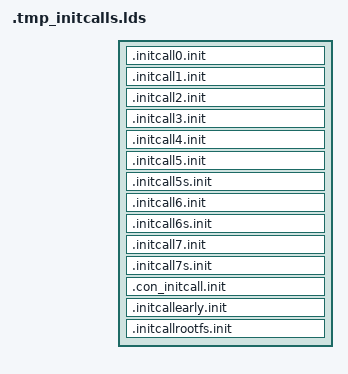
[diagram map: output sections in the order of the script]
SECTIONS {
	.initcall0.init : {
		*(.initcall0.init..kmod_shm__382_143_ipc_ns_init) ;
		*(.initcall0.init..kmod_min_addr__227_53_init_mmap_min_addr) ;
		*(.initcall0.init..kmod_pci__425_6677_pci_realloc_setup_params) ;
		*(.initcall0.init..kmod_net_namespace__599_1121_net_ns_init) ;
		*(.initcall0.init..kmod_inet_fragment__625_216_inet_frag_wq_init) ;
	}
	.initcall1.init : {
		*(.initcall1.init..kmod_e820__336_792_e820__register_nvs_regions) ;
		*(.initcall1.init..kmod_tsc__194_1029_cpufreq_register_tsc_scaling) ;
		*(.initcall1.init..kmod_reboot__371_525_reboot_init) ;
		*(.initcall1.init..kmod_apic__636_2793_init_lapic_sysfs) ;
		*(.initcall1.init..kmod_cpu__564_1558_alloc_frozen_cpus) ;
		*(.initcall1.init..kmod_cpu__566_1605_cpu_hotplug_pm_sync_init) ;
		*(.initcall1.init..kmod_workqueue__552_5647_wq_sysfs_init) ;
		*(.initcall1.init..kmod_ksysfs__245_269_ksysfs_init) ;
		*(.initcall1.init..kmod_cpufreq_schedutil__872_831_schedutil_gov_init) ;
		*(.initcall1.init..kmod_main__333_959_pm_init) ;
		*(.initcall1.init..kmod_hibernate__497_1271_pm_disk_init) ;
		*(.initcall1.init..kmod_swap__328_1613_swsusp_header_init) ;
		*(.initcall1.init..kmod_update__495_240_rcu_set_runtime_mode) ;
		*(.initcall1.init..kmod_jiffies__103_88_init_jiffies_clocksource) ;
		*(.initcall1.init..kmod_futex__347_4038_futex_init) ;
		*(.initcall1.init..kmod_cgroup__846_5876_cgroup_wq_init) ;
		*(.initcall1.init..kmod_cgroup_v1__363_1246_cgroup1_wq_init) ;
		*(.initcall1.init..kmod_trace_kprobe__325_1921_init_kprobe_trace_early) ;
		*(.initcall1.init..kmod_fsnotify__273_572_fsnotify_init) ;
		*(.initcall1.init..kmod_locks__492_3074_filelock_init) ;
		*(.initcall1.init..kmod_binfmt_misc__289_834_init_misc_binfmt) ;
		*(.initcall1.init..kmod_binfmt_script__201_156_init_script_binfmt) ;
		*(.initcall1.init..kmod_binfmt_elf__296_2311_init_elf_binfmt) ;
		*(.initcall1.init..kmod_compat_binfmt_elf__298_2311_init_compat_elf_binfmt) ;
		*(.initcall1.init..kmod_debugfs__283_851_debugfs_init) ;
		*(.initcall1.init..kmod_tracefs__253_552_tracefs_init) ;
		*(.initcall1.init..kmod_random32__401_489_prandom_init_early) ;
		*(.initcall1.init..kmod_iommu__402_2686_iommu_init) ;
		*(.initcall1.init..kmod_component__213_123_component_debug_init) ;
		*(.initcall1.init..kmod_trace__348_292_early_resume_init) ;
		*(.initcall1.init..kmod_cpufreq__572_2899_cpufreq_core_init) ;
		*(.initcall1.init..kmod_cpufreq_performance__180_44_cpufreq_gov_performance_init) ;
		*(.initcall1.init..kmod_cpufreq_userspace__186_141_cpufreq_gov_userspace_init) ;
		*(.initcall1.init..kmod_cpufreq_ondemand__198_477_CPU_FREQ_GOV_ONDEMAND_init) ;
		*(.initcall1.init..kmod_cpuidle__521_779_cpuidle_init) ;
		*(.initcall1.init..kmod_socket__658_3119_sock_init) ;
		*(.initcall1.init..kmod_sock__820_3497_net_inuse_init) ;
		*(.initcall1.init..kmod_net_namespace__566_384_net_defaults_init) ;
		*(.initcall1.init..kmod_flow_dissector__679_1832_init_default_flow_dissectors) ;
		*(.initcall1.init..kmod_netpoll__671_796_netpoll_init) ;
		*(.initcall1.init..kmod_af_netlink__689_2911_netlink_proto_init) ;
		*(.initcall1.init..kmod_genetlink__571_1443_genl_init) ;
		*(.initcall1.init..kmod_cpu__410_397_bsp_pm_check_init) ;
	}
	.initcall2.init : {
		*(.initcall2.init..kmod_irqdesc__175_331_irq_sysfs_init) ;
		*(.initcall2.init..kmod_audit__575_1677_audit_init) ;
		*(.initcall2.init..kmod_tracepoint__189_140_release_early_probes) ;
		*(.initcall2.init..kmod_backing_dev__527_230_bdi_class_init) ;
		*(.initcall2.init..kmod_mm_init__269_204_mm_sysfs_init) ;
		*(.initcall2.init..kmod_page_alloc__657_8484_init_per_zone_wmark_min) ;
		*(.initcall2.init..kmod_mpi__239_64_mpi_init) ;
		*(.initcall2.init..kmod_kobject_uevent__547_814_kobject_uevent_init) ;
		*(.initcall2.init..kmod_probe__261_108_pcibus_class_init) ;
		*(.initcall2.init..kmod_pci_driver__389_1661_pci_driver_init) ;
		*(.initcall2.init..kmod_backlight__360_770_backlight_class_init) ;
		*(.initcall2.init..kmod_tty_io__299_3559_tty_class_init) ;
		*(.initcall2.init..kmod_vt__303_4286_vtconsole_class_init) ;
		*(.initcall2.init..kmod_iommu_sysfs__236_47_iommu_dev_init) ;
		*(.initcall2.init..kmod_drm_mipi_dsi__378_1209_mipi_dsi_bus_init) ;
		*(.initcall2.init..kmod_core__394_606_devlink_class_init) ;
		*(.initcall2.init..kmod_swnode__215_1167_software_node_init) ;
		*(.initcall2.init..kmod_wakeup__542_1188_wakeup_sources_debugfs_init) ;
		*(.initcall2.init..kmod_wakeup_stats__165_217_wakeup_sources_sysfs_init) ;
		*(.initcall2.init..kmod_node__327_1073_register_node_type) ;
		*(.initcall2.init..kmod_regmap__457_3316_regmap_initcall) ;
		*(.initcall2.init..kmod_i2c_core__475_2090_i2c_init) ;
		*(.initcall2.init..kmod_thermal_sys__413_1489_thermal_init) ;
		*(.initcall2.init..kmod_menu__155_579_init_menu) ;
		*(.initcall2.init..kmod_pcc__178_615_pcc_init) ;
		*(.initcall2.init..kmod_amd_bus__253_404_amd_postcore_init) ;
	}
	.initcall3.init : {
		*(.initcall3.init..kmod_bts__264_619_bts_init) ;
		*(.initcall3.init..kmod_pt__306_1761_pt_init) ;
		*(.initcall3.init..kmod_ksysfs__234_356_boot_params_ksysfs_init) ;
		*(.initcall3.init..kmod_bootflag__259_102_sbf_init) ;
		*(.initcall3.init..kmod_kdebugfs__230_176_arch_kdebugfs_init) ;
		*(.initcall3.init..kmod_intel_pconfig__10_82_intel_pconfig_init) ;
		*(.initcall3.init..kmod_if__201_424_mtrr_if_init) ;
		*(.initcall3.init..kmod_cstate__192_214_ffh_cstate_init) ;
		*(.initcall3.init..kmod_kcmp__270_239_kcmp_cookies_init) ;
		*(.initcall3.init..kmod_cryptomgr__359_269_cryptomgr_init) ;
		*(.initcall3.init..kmod_pci_acpi__275_1389_acpi_pci_init) ;
		*(.initcall3.init..kmod_dmaengine__263_293_dma_channel_table_init) ;
		*(.initcall3.init..kmod_dmaengine__339_1659_dma_bus_init) ;
		*(.initcall3.init..kmod_dma_iommu__297_1428_iommu_dma_init) ;
		*(.initcall3.init..kmod_dmi_id__169_255_dmi_id_init) ;
		*(.initcall3.init..kmod_init__245_51_pci_arch_init) ;
	}
	.initcall4.init : {
		*(.initcall4.init..kmod_vma__339_457_init_vdso) ;
		*(.initcall4.init..kmod_vdso32_setup__67_63_sysenter_setup) ;
		*(.initcall4.init..kmod_core__304_6346_fixup_ht_bug) ;
		*(.initcall4.init..kmod_topology__168_167_topology_init) ;
		*(.initcall4.init..kmod_intel_epb__159_216_intel_epb_init) ;
		*(.initcall4.init..kmod_mtrr__251_887_mtrr_init_finialize) ;
		*(.initcall4.init..kmod_user__147_226_uid_cache_init) ;
		*(.initcall4.init..kmod_params__303_956_param_sysfs_init) ;
		*(.initcall4.init..kmod_ucount__155_319_user_namespace_sysctl_init) ;
		*(.initcall4.init..kmod_stats__708_128_proc_schedstat_init) ;
		*(.initcall4.init..kmod_poweroff__69_45_pm_sysrq_init) ;
		*(.initcall4.init..kmod_profile__261_565_create_proc_profile) ;
		*(.initcall4.init..kmod_crash_core__235_482_crash_save_vmcoreinfo_init) ;
		*(.initcall4.init..kmod_kexec_core__347_1119_crash_notes_memory_init) ;
		*(.initcall4.init..kmod_cgroup__861_6744_cgroup_sysfs_init) ;
		*(.initcall4.init..kmod_namespace__253_157_cgroup_namespaces_init) ;
		*(.initcall4.init..kmod_kprobes__374_2530_init_optprobes) ;
		*(.initcall4.init..kmod_oom_kill__423_682_oom_init) ;
		*(.initcall4.init..kmod_backing_dev__529_247_default_bdi_init) ;
		*(.initcall4.init..kmod_percpu__452_3381_percpu_enable_async) ;
		*(.initcall4.init..kmod_compaction__514_3012_kcompactd_init) ;
		*(.initcall4.init..kmod_mmap__429_3741_init_user_reserve) ;
		*(.initcall4.init..kmod_mmap__433_3762_init_admin_reserve) ;
		*(.initcall4.init..kmod_mmap__435_3832_init_reserve_notifier) ;
		*(.initcall4.init..kmod_swap_state__336_911_swap_init_sysfs) ;
		*(.initcall4.init..kmod_swapfile__436_3822_swapfile_init) ;
		*(.initcall4.init..kmod_hugetlb__381_3607_hugetlb_init) ;
		*(.initcall4.init..kmod_io_wq__357_1157_io_wq_init) ;
		*(.initcall4.init..kmod_seqiv__270_183_seqiv_module_init) ;
		*(.initcall4.init..kmod_echainiv__270_160_echainiv_module_init) ;
		*(.initcall4.init..kmod_rsa_generic__246_281_rsa_init) ;
		*(.initcall4.init..kmod_cmac__114_311_crypto_cmac_module_init) ;
		*(.initcall4.init..kmod_hmac__266_254_hmac_module_init) ;
		*(.initcall4.init..kmod_crypto_null__262_221_crypto_null_mod_init) ;
		*(.initcall4.init..kmod_md5__115_245_md5_mod_init) ;
		*(.initcall4.init..kmod_sha256_generic__252_113_sha256_generic_mod_init) ;
		*(.initcall4.init..kmod_sha512_generic__252_221_sha512_generic_mod_init) ;
		*(.initcall4.init..kmod_cbc__112_218_crypto_cbc_module_init) ;
		*(.initcall4.init..kmod_ctr__115_355_crypto_ctr_module_init) ;
		*(.initcall4.init..kmod_gcm__282_1159_crypto_gcm_module_init) ;
		*(.initcall4.init..kmod_ccm__284_949_crypto_ccm_module_init) ;
		*(.initcall4.init..kmod_aes_generic__107_1314_aes_init) ;
		*(.initcall4.init..kmod_crc32c_generic__114_161_crc32c_mod_init) ;
		*(.initcall4.init..kmod_authenc__393_464_crypto_authenc_module_init) ;
		*(.initcall4.init..kmod_authencesn__391_479_crypto_authenc_esn_module_init) ;
		*(.initcall4.init..kmod_drbg__280_2146_drbg_init) ;
		*(.initcall4.init..kmod_ghash_generic__117_178_ghash_mod_init) ;
		*(.initcall4.init..kmod_bio__525_1620_init_bio) ;
		*(.initcall4.init..kmod_blk_ioc__314_422_blk_ioc_init) ;
		*(.initcall4.init..kmod_blk_mq__582_4018_blk_mq_init) ;
		*(.initcall4.init..kmod_genhd__333_836_genhd_device_init) ;
		*(.initcall4.init..kmod_slot__271_380_pci_slot_init) ;
		*(.initcall4.init..kmod_acpi__360_1344_acpi_init) ;
		*(.initcall4.init..kmod_pnp__250_234_pnp_init) ;
		*(.initcall4.init..kmod_misc__223_291_misc_init) ;
		*(.initcall4.init..kmod_iommu__299_143_iommu_subsys_init) ;
		*(.initcall4.init..kmod_vgaarb__279_1588_vga_arb_device_init) ;
		*(.initcall4.init..kmod_cn__555_283_cn_init) ;
		*(.initcall4.init..kmod_dma_buf__305_1481_dma_buf_init) ;
		*(.initcall4.init..kmod_scsi_mod__405_812_init_scsi) ;
		*(.initcall4.init..kmod_libata__519_6313_ata_init) ;
		*(.initcall4.init..kmod_libphy__463_3242_phy_init) ;
		*(.initcall4.init..kmod_pcmcia_core__283_918_init_pcmcia_cs) ;
		*(.initcall4.init..kmod_usb_common__327_412_usb_common_init) ;
		*(.initcall4.init..kmod_usbcore__365_1119_usb_init) ;
		*(.initcall4.init..kmod_serio__226_1052_serio_init) ;
		*(.initcall4.init..kmod_input_core__367_2634_input_init) ;
		*(.initcall4.init..kmod_rtc_core__255_469_rtc_init) ;
		*(.initcall4.init..kmod_pps_core__218_484_pps_init) ;
		*(.initcall4.init..kmod_ptp__329_453_ptp_init) ;
		*(.initcall4.init..kmod_power_supply__201_1380_power_supply_class_init) ;
		*(.initcall4.init..kmod_hwmon__316_1071_hwmon_init) ;
		*(.initcall4.init..kmod_md_mod__720_9898_md_init) ;
		*(.initcall4.init..kmod_led_class__179_539_leds_init) ;
		*(.initcall4.init..kmod_dmi_scan__277_804_dmi_init) ;
		*(.initcall4.init..kmod_efi__295_436_efisubsys_init) ;
		*(.initcall4.init..kmod_nvmem_core__305_1913_nvmem_init) ;
		*(.initcall4.init..kmod_soundcore__170_65_init_soundcore) ;
		*(.initcall4.init..kmod_snd__239_426_alsa_sound_init) ;
		*(.initcall4.init..kmod_snd_seq_device__235_311_alsa_seq_device_init) ;
		*(.initcall4.init..kmod_snd_hda_core__248_96_hda_bus_init) ;
		*(.initcall4.init..kmod_sock__827_3809_proto_init) ;
		*(.initcall4.init..kmod_dev__1551_11719_net_dev_init) ;
		*(.initcall4.init..kmod_neighbour__730_3740_neigh_init) ;
		*(.initcall4.init..kmod_fib_notifier__367_199_fib_notifier_init) ;
		*(.initcall4.init..kmod_fib_rules__678_1298_fib_rules_init) ;
		*(.initcall4.init..kmod_sch_api__638_2305_pktsched_init) ;
		*(.initcall4.init..kmod_cls_api__743_3919_tc_filter_init) ;
		*(.initcall4.init..kmod_act_api__585_1711_tc_action_init) ;
		*(.initcall4.init..kmod_ethtool_nl__557_1004_ethnl_init) ;
		*(.initcall4.init..kmod_nexthop__739_3747_nexthop_init) ;
		*(.initcall4.init..kmod_cipso_ipv4__641_2293_cipso_v4_init) ;
		*(.initcall4.init..kmod_mac80211__1817_1489_ieee80211_init) ;
		*(.initcall4.init..kmod_netlabel_kapi__596_1523_netlbl_init) ;
		*(.initcall4.init..kmod_rfkill__294_1398_rfkill_init) ;
		*(.initcall4.init..kmod_legacy__246_77_pci_subsys_init) ;
	}
	.initcall5.init : {
		*(.initcall5.init..kmod_nmi__344_102_nmi_warning_debugfs) ;
		*(.initcall5.init..kmod_microcode__237_908_save_microcode_in_initrd) ;
		*(.initcall5.init..kmod_hpet__177_1084_hpet_late_init) ;
		*(.initcall5.init..kmod_amd_nb__254_544_init_amd_nbs) ;
		*(.initcall5.init..kmod_resource__276_1915_iomem_init_inode) ;
		*(.initcall5.init..kmod_clocksource__194_1000_clocksource_done_booting) ;
		*(.initcall5.init..kmod_trace__418_9700_tracer_init_tracefs) ;
		*(.initcall5.init..kmod_trace_printk__278_393_init_trace_printk_function_export) ;
		*(.initcall5.init..kmod_trace_kprobe__327_1951_init_kprobe_trace) ;
		*(.initcall5.init..kmod_trace_dynevent__278_236_init_dynamic_event) ;
		*(.initcall5.init..kmod_trace_uprobe__334_1664_init_uprobe_trace) ;
		*(.initcall5.init..kmod_secretmem__327_255_secretmem_init) ;
		*(.initcall5.init..kmod_pipe__342_1449_init_pipe_fs) ;
		*(.initcall5.init..kmod_inotify_user__360_855_inotify_user_setup) ;
		*(.initcall5.init..kmod_eventpoll__651_2386_eventpoll_init) ;
		*(.initcall5.init..kmod_anon_inodes__241_241_anon_inode_init) ;
		*(.initcall5.init..kmod_locks__490_3051_proc_locks_init) ;
		*(.initcall5.init..kmod_iomap__443_1537_iomap_init) ;
		*(.initcall5.init..kmod_dquot__368_2988_dquot_init) ;
		*(.initcall5.init..kmod_netlink__305_103_quota_init) ;
		*(.initcall5.init..kmod_proc__192_19_proc_cmdline_init) ;
		*(.initcall5.init..kmod_proc__208_98_proc_consoles_init) ;
		*(.initcall5.init..kmod_proc__221_32_proc_cpuinfo_init) ;
		*(.initcall5.init..kmod_proc__290_60_proc_devices_init) ;
		*(.initcall5.init..kmod_proc__192_42_proc_interrupts_init) ;
		*(.initcall5.init..kmod_proc__229_33_proc_loadavg_init) ;
		*(.initcall5.init..kmod_proc__313_161_proc_meminfo_init) ;
		*(.initcall5.init..kmod_proc__210_242_proc_stat_init) ;
		*(.initcall5.init..kmod_proc__192_41_proc_uptime_init) ;
		*(.initcall5.init..kmod_proc__192_23_proc_version_init) ;
		*(.initcall5.init..kmod_proc__192_33_proc_softirqs_init) ;
		*(.initcall5.init..kmod_proc__279_697_proc_kcore_init) ;
		*(.initcall5.init..kmod_proc__287_1560_vmcore_init) ;
		*(.initcall5.init..kmod_proc__190_66_proc_kmsg_init) ;
		*(.initcall5.init..kmod_proc__319_338_proc_page_init) ;
		*(.initcall5.init..kmod_ramfs__307_295_init_ramfs_fs) ;
		*(.initcall5.init..kmod_hugetlbfs__314_1584_init_hugetlbfs_fs) ;
		*(.initcall5.init..kmod_scsi_ioctl__322_890_blk_scsi_ioctl_init) ;
		*(.initcall5.init..kmod_acpi__316_183_acpi_event_init) ;
		*(.initcall5.init..kmod_pnp__164_113_pnp_system_init) ;
		*(.initcall5.init..kmod_pnp__187_314_pnpacpi_init) ;
		*(.initcall5.init..kmod_mem__324_777_chr_dev_init) ;
		*(.initcall5.init..kmod_firmware_class__336_1576_firmware_class_init) ;
		*(.initcall5.init..kmod_pcmcia__299_1441_init_pcmcia_bus) ;
		*(.initcall5.init..kmod_acpi_pm__254_220_init_acpi_pm_clocksource) ;
		*(.initcall5.init..kmod_sysctl_net_core__599_663_sysctl_core_init) ;
		*(.initcall5.init..kmod_eth__617_505_eth_offload_init) ;
		*(.initcall5.init..kmod_af_inet__751_1929_ipv4_offload_init) ;
		*(.initcall5.init..kmod_af_inet__754_2062_inet_init) ;
		*(.initcall5.init..kmod_unix__588_2990_af_unix_init) ;
		*(.initcall5.init..kmod_ip6_offload__626_446_ipv6_offload_init) ;
		*(.initcall5.init..kmod_sunrpc__569_152_init_sunrpc) ;
		*(.initcall5.init..kmod_cfg80211__1734_1570_cfg80211_init) ;
		*(.initcall5.init..kmod_i386__259_373_pcibios_assign_resources) ;
	}
	.initcall5s.init : {
		*(.initcall5s.init..kmod_quirks__326_194_pci_apply_final_quirks) ;
		*(.initcall5s.init..kmod_acpi__305_142_acpi_reserve_resources) ;
	}
	.initcall6.init : {
		*(.initcall6.init..kmod_vdso32_setup__69_96_ia32_binfmt_init) ;
		*(.initcall6.init..kmod_rapl__267_859_rapl_pmu_init) ;
		*(.initcall6.init..kmod_uncore__268_670_amd_uncore_init) ;
		*(.initcall6.init..kmod_ibs__287_1069_amd_ibs_init) ;
		*(.initcall6.init..kmod_iommu__270_489_amd_iommu_pc_init) ;
		*(.initcall6.init..kmod_msr__258_308_msr_init) ;
		*(.initcall6.init..kmod_intel_uncore__306_1876_intel_uncore_init) ;
		*(.initcall6.init..kmod_intel_cstate__264_777_cstate_pmu_init) ;
		*(.initcall6.init..kmod_setup__393_1259_register_kernel_offset_dumper) ;
		*(.initcall6.init..kmod_i8259__204_434_i8259A_init_ops) ;
		*(.initcall6.init..kmod_tsc__199_1416_init_tsc_clocksource) ;
		*(.initcall6.init..kmod_rtc__298_207_add_rtc_cmos) ;
		*(.initcall6.init..kmod_i8237__95_76_i8237A_init_ops) ;
		*(.initcall6.init..kmod_umwait__316_238_umwait_init) ;
		*(.initcall6.init..kmod_msr__239_286_msr_init) ;
		*(.initcall6.init..kmod_cpuid__210_178_cpuid_init) ;
		*(.initcall6.init..kmod_io_apic__325_2462_ioapic_init_ops) ;
		*(.initcall6.init..kmod_pcspeaker__159_14_add_pcspkr) ;
		*(.initcall6.init..kmod_check__234_186_start_periodic_check_for_corruption) ;
		*(.initcall6.init..kmod_sysfb__332_70_sysfb_init) ;
		*(.initcall6.init..kmod_audit_64__231_83_audit_classes_init) ;
		*(.initcall6.init..kmod_iosf_mbi__269_566_iosf_mbi_init) ;
		*(.initcall6.init..kmod_exec_domain__264_35_proc_execdomains_init) ;
		*(.initcall6.init..kmod_panic__269_676_register_warn_debugfs) ;
		*(.initcall6.init..kmod_cpu__579_2525_cpuhp_sysfs_init) ;
		*(.initcall6.init..kmod_resource__241_145_ioresources_init) ;
		*(.initcall6.init..kmod_user__314_451_snapshot_device_init) ;
		*(.initcall6.init..kmod_pm__316_249_irq_pm_init_ops) ;
		*(.initcall6.init..kmod_timekeeping__274_1897_timekeeping_init_ops) ;
		*(.initcall6.init..kmod_clocksource__213_1401_init_clocksource_sysfs) ;
		*(.initcall6.init..kmod_timer_list__242_359_init_timer_list_procfs) ;
		*(.initcall6.init..kmod_alarmtimer__349_939_alarmtimer_init) ;
		*(.initcall6.init..kmod_posix_timers__270_280_init_posix_timers) ;
		*(.initcall6.init..kmod_clockevents__198_776_clockevents_init_sysfs) ;
		*(.initcall6.init..kmod_dma__192_144_proc_dma_init) ;
		*(.initcall6.init..kmod_module__410_4622_proc_modules_init) ;
		*(.initcall6.init..kmod_kallsyms__416_866_kallsyms_init) ;
		*(.initcall6.init..kmod_pid_namespace__270_460_pid_namespaces_init) ;
		*(.initcall6.init..kmod_audit_watch__324_503_audit_watch_init) ;
		*(.initcall6.init..kmod_audit_fsnotify__304_192_audit_fsnotify_init) ;
		*(.initcall6.init..kmod_audit_tree__333_1085_audit_tree_init) ;
		*(.initcall6.init..kmod_seccomp__504_2387_seccomp_sysctl_init) ;
		*(.initcall6.init..kmod_utsname_sysctl__127_144_utsname_sysctl_init) ;
		*(.initcall6.init..kmod_tracepoint__226_738_init_tracepoints) ;
		*(.initcall6.init..kmod_blktrace__495_1597_init_blk_tracer) ;
		*(.initcall6.init..kmod_core__816_13370_perf_event_sysfs_init) ;
		*(.initcall6.init..kmod_system_keyring__144_135_system_trusted_keyring_init) ;
		*(.initcall6.init..kmod_vmscan__516_4336_kswapd_init) ;
		*(.initcall6.init..kmod_vmstat__338_2185_extfrag_debug_init) ;
		*(.initcall6.init..kmod_mm_init__267_192_mm_compute_batch_init) ;
		*(.initcall6.init..kmod_slab_common__472_1182_slab_proc_init) ;
		*(.initcall6.init..kmod_workingset__319_627_workingset_init) ;
		*(.initcall6.init..kmod_vmalloc__445_3910_proc_vmalloc_init) ;
		*(.initcall6.init..kmod_swapfile__391_2823_procswaps_init) ;
		*(.initcall6.init..kmod_slub__505_5731_slab_sysfs_init) ;
		*(.initcall6.init..kmod_slub__513_5899_slab_debugfs_init) ;
		*(.initcall6.init..kmod_fcntl__295_1056_fcntl_init) ;
		*(.initcall6.init..kmod_filesystems__267_251_proc_filesystems_init) ;
		*(.initcall6.init..kmod_fs_writeback__631_2341_start_dirtytime_writeback) ;
		*(.initcall6.init..kmod_block_dev__327_518_blkdev_init) ;
		*(.initcall6.init..kmod_direct_io__308_1379_dio_init) ;
		*(.initcall6.init..kmod_dnotify__251_392_dnotify_init) ;
		*(.initcall6.init..kmod_aio__323_279_aio_setup) ;
		*(.initcall6.init..kmod_io_uring__1032_10315_io_uring_init) ;
		*(.initcall6.init..kmod_mbcache__229_432_mbcache_init) ;
		*(.initcall6.init..kmod_grace__314_143_init_grace) ;
		*(.initcall6.init..kmod_quota_v2__212_436_init_v2_quota_format) ;
		*(.initcall6.init..kmod_devpts__252_637_init_devpts_fs) ;
		*(.initcall6.init..kmod_ext4__1507_6807_ext4_init_fs) ;
		*(.initcall6.init..kmod_jbd2__611_3190_journal_init) ;
		*(.initcall6.init..kmod_fat__330_1979_init_fat_fs) ;
		*(.initcall6.init..kmod_vfat__267_1084_init_vfat_fs) ;
		*(.initcall6.init..kmod_msdos__262_688_init_msdos_fs) ;
		*(.initcall6.init..kmod_isofs__301_1612_init_iso9660_fs) ;
		*(.initcall6.init..kmod_nfs__1044_2449_init_nfs_fs) ;
		*(.initcall6.init..kmod_nfsv2__577_31_init_nfs_v2) ;
		*(.initcall6.init..kmod_nfsv3__577_35_init_nfs_v3) ;
		*(.initcall6.init..kmod_nfsv4__579_313_init_nfs_v4) ;
		*(.initcall6.init..kmod_lockd__598_766_init_nlm) ;
		*(.initcall6.init..kmod_nls_cp437__99_384_init_nls_cp437) ;
		*(.initcall6.init..kmod_nls_ascii__99_163_init_nls_ascii) ;
		*(.initcall6.init..kmod_nls_iso8859_1__99_254_init_nls_iso8859_1) ;
		*(.initcall6.init..kmod_nls_utf8__99_65_init_nls_utf8) ;
		*(.initcall6.init..kmod_autofs4__210_44_init_autofs_fs) ;
		*(.initcall6.init..kmod_util__294_99_ipc_init) ;
		*(.initcall6.init..kmod_ipc_sysctl__204_243_ipc_sysctl_init) ;
		*(.initcall6.init..kmod_mqueue__586_1740_init_mqueue_fs) ;
		*(.initcall6.init..kmod_proc__229_58_key_proc_init) ;
		*(.initcall6.init..kmod_selinux__707_7538_selinux_nf_ip_init) ;
		*(.initcall6.init..kmod_selinux__618_2248_init_sel_fs) ;
		*(.initcall6.init..kmod_selinux__318_121_selnl_init) ;
		*(.initcall6.init..kmod_selinux__615_279_sel_netif_init) ;
		*(.initcall6.init..kmod_selinux__621_304_sel_netnode_init) ;
		*(.initcall6.init..kmod_selinux__618_238_sel_netport_init) ;
		*(.initcall6.init..kmod_selinux__676_3826_aurule_init) ;
		*(.initcall6.init..kmod_crypto_algapi__423_1275_crypto_algapi_init) ;
		*(.initcall6.init..kmod_jitterentropy_rng__107_217_jent_mod_init) ;
		*(.initcall6.init..kmod_asymmetric_keys__224_653_asymmetric_key_init) ;
		*(.initcall6.init..kmod_x509_key_parser__212_270_x509_key_init) ;
		*(.initcall6.init..kmod_genhd__350_1196_proc_genhd_init) ;
		*(.initcall6.init..kmod_bsg__314_524_bsg_init) ;
		*(.initcall6.init..kmod_mq_deadline__467_1125_deadline_init) ;
		*(.initcall6.init..kmod_kyber_iosched__524_1047_kyber_init) ;
		*(.initcall6.init..kmod_percpu_counter__178_257_percpu_counter_startup) ;
		*(.initcall6.init..kmod_sg_pool__243_190_sg_pool_init) ;
		*(.initcall6.init..kmod_pcieportdrv__250_271_pcie_portdrv_init) ;
		*(.initcall6.init..kmod_proc__251_468_pci_proc_init) ;
		*(.initcall6.init..kmod_pci_hotplug__286_573_pci_hotplug_init) ;
		*(.initcall6.init..kmod_acpi__181_196_ged_driver_init) ;
		*(.initcall6.init..kmod_ac__182_354_acpi_ac_init) ;
		*(.initcall6.init..kmod_button__236_648_acpi_button_driver_init) ;
		*(.initcall6.init..kmod_fan__189_496_acpi_fan_driver_init) ;
		*(.initcall6.init..kmod_video__379_2318_acpi_video_init) ;
		*(.initcall6.init..kmod_processor__196_360_acpi_processor_driver_init) ;
		*(.initcall6.init..kmod_thermal__198_1232_acpi_thermal_init) ;
		*(.initcall6.init..kmod_battery__339_1318_acpi_battery_init) ;
		*(.initcall6.init..kmod_bgrt__176_101_bgrt_init) ;
		*(.initcall6.init..kmod_clk_gpio__206_249_gpio_clk_driver_init) ;
		*(.initcall6.init..kmod_clk_pmc_atom__169_390_plt_clk_driver_init) ;
		*(.initcall6.init..kmod_n_null__213_63_n_null_init) ;
		*(.initcall6.init..kmod_pty__244_957_pty_init) ;
		*(.initcall6.init..kmod_sysrq__338_1193_sysrq_init) ;
		*(.initcall6.init..kmod_8250__307_1237_serial8250_init) ;
		*(.initcall6.init..kmod_8250_pci__296_5785_serial_pci_driver_init) ;
		*(.initcall6.init..kmod_8250_exar__296_870_exar_pci_driver_init) ;
		*(.initcall6.init..kmod_8250_lpss__294_399_lpss8250_pci_driver_init) ;
		*(.initcall6.init..kmod_8250_mid__293_391_mid8250_pci_driver_init) ;
		*(.initcall6.init..kmod_hpet__253_1076_hpet_init) ;
		*(.initcall6.init..kmod_nvram__304_540_nvram_module_init) ;
		*(.initcall6.init..kmod_rng_core__242_641_hwrng_modinit) ;
		*(.initcall6.init..kmod_via_rng__99_212_mod_init) ;
		*(.initcall6.init..kmod_agpgart__285_364_agp_init) ;
		*(.initcall6.init..kmod_amd64_agp__251_814_agp_amd64_mod_init) ;
		*(.initcall6.init..kmod_intel_agp__298_920_agp_intel_init) ;
		*(.initcall6.init..kmod_drm_kms_helper__347_87_drm_kms_helper_init) ;
		*(.initcall6.init..kmod_drm__363_1069_drm_core_init) ;
		*(.initcall6.init..kmod_i915__491_1217_i915_init) ;
		*(.initcall6.init..kmod_cn_proc__550_403_cn_proc_init) ;
		*(.initcall6.init..kmod_topology__237_143_topology_sysfs_init) ;
		*(.initcall6.init..kmod_cacheinfo__176_674_cacheinfo_sysfs_init) ;
		*(.initcall6.init..kmod_loop__360_2601_loop_init) ;
		*(.initcall6.init..kmod_mac_hid__218_274_mac_hid_init) ;
		*(.initcall6.init..kmod_scsi_transport_spi__418_1639_spi_transport_init) ;
		*(.initcall6.init..kmod_sd_mod__390_3811_init_sd) ;
		*(.initcall6.init..kmod_sr_mod__315_1073_init_sr) ;
		*(.initcall6.init..kmod_sg__352_2633_init_sg) ;
		*(.initcall6.init..kmod_ahci__349_1937_ahci_pci_driver_init) ;
		*(.initcall6.init..kmod_ata_piix__330_1786_piix_init) ;
		*(.initcall6.init..kmod_pata_amd__354_636_amd_pci_driver_init) ;
		*(.initcall6.init..kmod_pata_oldpiix__315_268_oldpiix_pci_driver_init) ;
		*(.initcall6.init..kmod_pata_sch__319_167_sch_pci_driver_init) ;
		*(.initcall6.init..kmod_Space__351_152_net_olddevs_init) ;
		*(.initcall6.init..kmod_loopback__555_277_blackhole_netdev_init) ;
		*(.initcall6.init..kmod_fixed_phy__400_369_fixed_mdio_bus_init) ;
		*(.initcall6.init..kmod_realtek__301_1029_phy_module_init) ;
		*(.initcall6.init..kmod_tg3__672_18314_tg3_driver_init) ;
		*(.initcall6.init..kmod_e100__394_3179_e100_init_module) ;
		*(.initcall6.init..kmod_e1000__594_238_e1000_init_module) ;
		*(.initcall6.init..kmod_e1000e__630_7906_e1000_init_module) ;
		*(.initcall6.init..kmod_sky2__609_5291_sky2_init_module) ;
		*(.initcall6.init..kmod_forcedeth__390_6493_forcedeth_pci_driver_init) ;
		*(.initcall6.init..kmod_8139too__387_2676_rtl8139_init_module) ;
		*(.initcall6.init..kmod_r8169__672_5454_rtl8169_pci_driver_init) ;
		*(.initcall6.init..kmod_cdrom__331_3776_cdrom_init) ;
		*(.initcall6.init..kmod_pcmcia_rsrc__253_1233_nonstatic_sysfs_init) ;
		*(.initcall6.init..kmod_yenta_socket__280_1456_yenta_cardbus_driver_init) ;
		*(.initcall6.init..kmod_usbmon__232_432_mon_init) ;
		*(.initcall6.init..kmod_ehci_hcd__412_1380_ehci_hcd_init) ;
		*(.initcall6.init..kmod_ehci_pci__261_423_ehci_pci_init) ;
		*(.initcall6.init..kmod_ohci_hcd__378_1347_ohci_hcd_mod_init) ;
		*(.initcall6.init..kmod_ohci_pci__262_321_ohci_pci_init) ;
		*(.initcall6.init..kmod_uhci_hcd__360_938_uhci_hcd_init) ;
		*(.initcall6.init..kmod_xhci_hcd__681_5502_xhci_hcd_init) ;
		*(.initcall6.init..kmod_xhci_pci__642_675_xhci_pci_init) ;
		*(.initcall6.init..kmod_usblp__225_1468_usblp_driver_init) ;
		*(.initcall6.init..kmod_usb_storage__336_1159_usb_storage_driver_init) ;
		*(.initcall6.init..kmod_i8042__348_1658_i8042_init) ;
		*(.initcall6.init..kmod_serport__224_310_serport_init) ;
		*(.initcall6.init..kmod_input_leds__218_209_input_leds_init) ;
		*(.initcall6.init..kmod_evdev__266_1441_evdev_init) ;
		*(.initcall6.init..kmod_atkbd__238_1913_atkbd_init) ;
		*(.initcall6.init..kmod_psmouse__240_2087_psmouse_init) ;
		*(.initcall6.init..kmod_rtc_cmos__263_1486_cmos_init) ;
		*(.initcall6.init..kmod_i2c_smbus__322_198_smbalert_driver_init) ;
		*(.initcall6.init..kmod_i2c_i801__335_1984_i2c_i801_init) ;
		*(.initcall6.init..kmod_therm_throt__339_517_thermal_throttle_init_device) ;
		*(.initcall6.init..kmod_dm_mod__517_3063_dm_init) ;
		*(.initcall6.init..kmod_dm_mirror__303_1492_dm_mirror_init) ;
		*(.initcall6.init..kmod_dm_log__298_885_dm_dirty_log_init) ;
		*(.initcall6.init..kmod_dm_zero__292_83_dm_zero_init) ;
		*(.initcall6.init..kmod_intel_pstate__514_3346_intel_pstate_init) ;
		*(.initcall6.init..kmod_efivars__263_669_efivars_sysfs_init) ;
		*(.initcall6.init..kmod_esrt__276_432_esrt_sysfs_init) ;
		*(.initcall6.init..kmod_hid__305_2627_hid_init) ;
		*(.initcall6.init..kmod_hid_generic__217_82_hid_generic_init) ;
		*(.initcall6.init..kmod_hid_a4tech__216_164_a4_driver_init) ;
		*(.initcall6.init..kmod_hid_apple__224_637_apple_driver_init) ;
		*(.initcall6.init..kmod_hid_belkin__216_86_belkin_driver_init) ;
		*(.initcall6.init..kmod_hid_cherry__216_69_ch_driver_init) ;
		*(.initcall6.init..kmod_hid_chicony__225_150_ch_driver_init) ;
		*(.initcall6.init..kmod_hid_cypress__216_177_cp_driver_init) ;
		*(.initcall6.init..kmod_hid_ezkey__216_76_ez_driver_init) ;
		*(.initcall6.init..kmod_hid_gyration__216_88_gyration_driver_init) ;
		*(.initcall6.init..kmod_hid_ite__216_136_ite_driver_init) ;
		*(.initcall6.init..kmod_hid_kensington__216_47_ks_driver_init) ;
		*(.initcall6.init..kmod_hid_logitech__227_931_lg_driver_init) ;
		*(.initcall6.init..kmod_hid_lg_g15__242_953_lg_g15_driver_init) ;
		*(.initcall6.init..kmod_hid_microsoft__218_467_ms_driver_init) ;
		*(.initcall6.init..kmod_hid_monterey__216_63_mr_driver_init) ;
		*(.initcall6.init..kmod_hid_ntrig__253_1030_ntrig_driver_init) ;
		*(.initcall6.init..kmod_hid_pl__219_220_pl_driver_init) ;
		*(.initcall6.init..kmod_hid_petalynx__216_103_pl_driver_init) ;
		*(.initcall6.init..kmod_hid_redragon__216_60_redragon_driver_init) ;
		*(.initcall6.init..kmod_hid_samsung__225_194_samsung_driver_init) ;
		*(.initcall6.init..kmod_hid_sony__249_3215_sony_init) ;
		*(.initcall6.init..kmod_hid_sunplus__216_63_sp_driver_init) ;
		*(.initcall6.init..kmod_hid_topseed__216_79_ts_driver_init) ;
		*(.initcall6.init..kmod_usbhid__292_1703_hid_init) ;
		*(.initcall6.init..kmod_eeepc_laptop__354_1510_eeepc_laptop_init) ;
		*(.initcall6.init..kmod_pmc_atom__249_532_pmc_atom_init) ;
		*(.initcall6.init..kmod_snd_hwdep__235_544_alsa_hwdep_init) ;
		*(.initcall6.init..kmod_snd_timer__296_2347_alsa_timer_init) ;
		*(.initcall6.init..kmod_snd_hrtimer__176_168_snd_hrtimer_init) ;
		*(.initcall6.init..kmod_snd_pcm__267_1232_alsa_pcm_init) ;
		*(.initcall6.init..kmod_snd_seq__234_119_alsa_seq_init) ;
		*(.initcall6.init..kmod_snd_seq_dummy__226_212_alsa_seq_dummy_init) ;
		*(.initcall6.init..kmod_snd_hda_intel__455_2769_azx_driver_init) ;
		*(.initcall6.init..kmod_sock_diag__568_339_sock_diag_init) ;
		*(.initcall6.init..kmod_sch_blackhole__387_41_blackhole_init) ;
		*(.initcall6.init..kmod_nfnetlink__569_730_nfnetlink_init) ;
		*(.initcall6.init..kmod_nfnetlink_log__647_1204_nfnetlink_log_init) ;
		*(.initcall6.init..kmod_nf_conntrack__628_1252_nf_conntrack_standalone_init) ;
		*(.initcall6.init..kmod_nf_conntrack_netlink__640_3905_ctnetlink_init) ;
		*(.initcall6.init..kmod_nf_conntrack_ftp__678_613_nf_conntrack_ftp_init) ;
		*(.initcall6.init..kmod_nf_conntrack_irc__630_284_nf_conntrack_irc_init) ;
		*(.initcall6.init..kmod_nf_conntrack_sip__704_1701_nf_conntrack_sip_init) ;
		*(.initcall6.init..kmod_nf_nat__656_1169_nf_nat_init) ;
		*(.initcall6.init..kmod_nf_nat_ftp__624_150_nf_nat_ftp_init) ;
		*(.initcall6.init..kmod_nf_nat_irc__624_121_nf_nat_irc_init) ;
		*(.initcall6.init..kmod_nf_nat_sip__627_687_nf_nat_sip_init) ;
		*(.initcall6.init..kmod_x_tables__719_1953_xt_init) ;
		*(.initcall6.init..kmod_xt_tcpudp__639_231_tcpudp_mt_init) ;
		*(.initcall6.init..kmod_xt_CONNSECMARK__623_138_connsecmark_tg_init) ;
		*(.initcall6.init..kmod_xt_NFLOG__361_80_nflog_tg_init) ;
		*(.initcall6.init..kmod_xt_SECMARK__362_190_secmark_tg_init) ;
		*(.initcall6.init..kmod_xt_TCPMSS__639_344_tcpmss_tg_init) ;
		*(.initcall6.init..kmod_xt_conntrack__623_326_conntrack_mt_init) ;
		*(.initcall6.init..kmod_xt_policy__596_186_policy_mt_init) ;
		*(.initcall6.init..kmod_xt_state__622_74_state_mt_init) ;
		*(.initcall6.init..kmod_gre_offload__608_294_gre_offload_init) ;
		*(.initcall6.init..kmod_sysctl_net_ipv4__637_1489_sysctl_ipv4_init) ;
		*(.initcall6.init..kmod_tunnel4__597_295_tunnel4_init) ;
		*(.initcall6.init..kmod_nf_defrag_ipv4__626_182_nf_defrag_init) ;
		*(.initcall6.init..kmod_ip_tables__596_1947_ip_tables_init) ;
		*(.initcall6.init..kmod_iptable_filter__587_108_iptable_filter_init) ;
		*(.initcall6.init..kmod_iptable_mangle__586_145_iptable_mangle_init) ;
		*(.initcall6.init..kmod_ipt_REJECT__586_110_reject_tg_init) ;
		*(.initcall6.init..kmod_tcp_cubic__645_525_cubictcp_register) ;
		*(.initcall6.init..kmod_xfrm_user__605_3533_xfrm_user_init) ;
		*(.initcall6.init..kmod_ipv6__701_1286_inet6_init) ;
		*(.initcall6.init..kmod_ah6__624_799_ah6_init) ;
		*(.initcall6.init..kmod_esp6__685_1285_esp6_init) ;
		*(.initcall6.init..kmod_ip6_tables__641_1955_ip6_tables_init) ;
		*(.initcall6.init..kmod_ip6table_filter__632_109_ip6table_filter_init) ;
		*(.initcall6.init..kmod_ip6table_mangle__631_135_ip6table_mangle_init) ;
		*(.initcall6.init..kmod_nf_defrag_ipv6__669_177_nf_defrag_init) ;
		*(.initcall6.init..kmod_ip6t_ipv6header__631_152_ipv6header_mt6_init) ;
		*(.initcall6.init..kmod_ip6t_REJECT__631_120_reject_tg6_init) ;
		*(.initcall6.init..kmod_sit__670_2019_sit_init) ;
		*(.initcall6.init..kmod_af_packet__677_4704_packet_init) ;
		*(.initcall6.init..kmod_auth_rpcgss__818_2262_init_rpcsec_gss) ;
		*(.initcall6.init..kmod_dns_resolver__215_382_init_dns_resolver) ;
		*(.initcall6.init..kmod_cpu__412_510_pm_check_save_msr) ;
	}
	.initcall6s.init : {
		*(.initcall6s.init..kmod_core__371_2706_mcheck_init_device) ;
	}
	.initcall7.init : {
		*(.initcall7.init..kmod_core__373_2782_mcheck_late_init) ;
		*(.initcall7.init..kmod_severity__335_487_severities_debugfs_init) ;
		*(.initcall7.init..kmod_microcode__239_909_microcode_init) ;
		*(.initcall7.init..kmod_boot__319_940_hpet_insert_resource) ;
		*(.initcall7.init..kmod_mpparse__294_944_update_mp_table) ;
		*(.initcall7.init..kmod_apic__638_2933_lapic_insert_resource) ;
		*(.initcall7.init..kmod_ipi__69_27_print_ipi_mode) ;
		*(.initcall7.init..kmod_vector__596_1340_print_ICs) ;
		*(.initcall7.init..kmod_tlb__268_1269_create_tlb_single_page_flush_ceiling) ;
		*(.initcall7.init..kmod_memtype__244_1218_pat_memtype_list_init) ;
		*(.initcall7.init..kmod_pkeys__251_181_create_init_pkru_value) ;
		*(.initcall7.init..kmod_panic__266_553_init_oops_id) ;
		*(.initcall7.init..kmod_reboot__339_891_reboot_ksysfs_init) ;
		*(.initcall7.init..kmod_clock__708_243_sched_clock_init_late) ;
		*(.initcall7.init..kmod_qos__441_424_cpu_latency_qos_init) ;
		*(.initcall7.init..kmod_main__330_460_pm_debugfs_init) ;
		*(.initcall7.init..kmod_printk__329_3144_printk_late_init) ;
		*(.initcall7.init..kmod_srcutree__408_1468_init_srcu_module_notifier) ;
		*(.initcall7.init..kmod_swiotlb__311_685_swiotlb_create_debugfs) ;
		*(.initcall7.init..kmod_timekeeping_debug__313_44_tk_debug_sleep_time_init) ;
		*(.initcall7.init..kmod_kprobes__391_2826_debugfs_kprobe_init) ;
		*(.initcall7.init..kmod_taskstats__328_698_taskstats_init) ;
		*(.initcall7.init..kmod_system_keyring__146_167_load_system_certificate_list) ;
		*(.initcall7.init..kmod_memory__496_4093_fault_around_debugfs) ;
		*(.initcall7.init..kmod_swapfile__394_2832_max_swapfiles_check) ;
		*(.initcall7.init..kmod_early_ioremap__240_103_check_early_ioremap_leak) ;
		*(.initcall7.init..kmod_process_keys__313_957_init_root_keyring) ;
		*(.initcall7.init..kmod_integrity__235_232_integrity_fs_init) ;
		*(.initcall7.init..kmod_blk_timeout__299_99_blk_timeout_init) ;
		*(.initcall7.init..kmod_random32__407_632_prandom_init_late) ;
		*(.initcall7.init..kmod_error_inject__263_244_init_error_injection) ;
		*(.initcall7.init..kmod_pci__422_6502_pci_resource_alignment_sysfs_init) ;
		*(.initcall7.init..kmod_pci_sysfs__291_1423_pci_sysfs_init) ;
		*(.initcall7.init..kmod_clk__564_3363_clk_debug_init) ;
		*(.initcall7.init..kmod_dmar__371_2163_dmar_free_unused_resources) ;
		*(.initcall7.init..kmod_core__425_1136_sync_state_resume_initcall) ;
		*(.initcall7.init..kmod_dd__254_352_deferred_probe_initcall) ;
		*(.initcall7.init..kmod_trace__350_293_late_resume_init) ;
		*(.initcall7.init..kmod_netconsole__381_973_init_netconsole) ;
		*(.initcall7.init..kmod_acpi_cpufreq__200_1059_acpi_cpufreq_init) ;
		*(.initcall7.init..kmod_memmap__246_417_firmware_memmap_init) ;
		*(.initcall7.init..kmod_efi__303_1036_register_update_efi_random_seed) ;
		*(.initcall7.init..kmod_reboot__242_77_efi_shutdown_init) ;
		*(.initcall7.init..kmod_earlycon__244_50_efi_earlycon_unmap_fb) ;
		*(.initcall7.init..kmod_tcp_cong__628_256_tcp_congestion_default) ;
		*(.initcall7.init..kmod_ipconfig__597_1642_ip_auto_config) ;
		*(.initcall7.init..kmod_cfg80211__1758_4259_regulatory_init_db) ;
		*(.initcall7.init..kmod_mmconfig_shared__273_718_pci_mmcfg_late_insert_resources) ;
	}
	.initcall7s.init : {
		*(.initcall7s.init..kmod_hibernate__495_1023_software_resume) ;
		*(.initcall7s.init..kmod_trace__416_9576_trace_eval_sync) ;
		*(.initcall7s.init..kmod_trace__423_10173_late_trace_init) ;
		*(.initcall7s.init..kmod_clk__514_1320_clk_disable_unused) ;
		*(.initcall7s.init..kmod_last__161_29_alsa_sound_last_init) ;
	}
	.con_initcall.init : {
		*(.con_initcall.init..kmod_vt__285_3509_con_init) ;
		*(.con_initcall.init..kmod_8250__300_683_univ8250_console_init) ;
	}
	.initcallearly.init : {
		*(.initcallearly.init..kmod_core__328_2212_init_hw_perf_events) ;
		*(.initcallearly.init..kmod_init__228_177_init_real_mode) ;
		*(.initcallearly.init..kmod_irq__646_75_trace_init_perf_perm_irq_work_exit) ;
		*(.initcallearly.init..kmod_apic__630_1907_validate_x2apic) ;
		*(.initcallearly.init..kmod_hw_nmi__251_58_register_nmi_cpu_backtrace_handler) ;
		*(.initcallearly.init..kmod_softirq__328_973_spawn_ksoftirqd) ;
		*(.initcallearly.init..kmod_core__977_8848_migration_init) ;
		*(.initcallearly.init..kmod_srcutree__404_1387_srcu_bootup_announce) ;
		*(.initcallearly.init..kmod_tree__744_4489_rcu_spawn_gp_kthread) ;
		*(.initcallearly.init..kmod_tree__763_105_check_cpu_stall_init) ;
		*(.initcallearly.init..kmod_tree__827_966_rcu_sysrq_init) ;
		*(.initcallearly.init..kmod_common__345_42_trace_init_flags_sys_enter) ;
		*(.initcallearly.init..kmod_common__347_66_trace_init_flags_sys_exit) ;
		*(.initcallearly.init..kmod_stop_machine__243_586_cpu_stop_init) ;
		*(.initcallearly.init..kmod_kprobes__372_2516_init_kprobes) ;
		*(.initcallearly.init..kmod_trace_output__768_1585_init_events) ;
		*(.initcallearly.init..kmod_trace_printk__280_400_init_trace_printk) ;
		*(.initcallearly.init..kmod_trace_events__654_3661_event_trace_enable_again) ;
		*(.initcallearly.init..kmod_static_call__175_500_static_call_init) ;
		*(.initcallearly.init..kmod_jump_label__207_774_jump_label_init_module) ;
		*(.initcallearly.init..kmod_memory__439_168_init_zero_pfn) ;
		*(.initcallearly.init..kmod_vsprintf__606_792_initialize_ptr_random) ;
		*(.initcallearly.init..kmod_efi__299_993_efi_memreserve_root_init) ;
		*(.initcallearly.init..kmod_earlycon__242_41_efi_earlycon_remap_fb) ;
	}
	.initcallrootfs.init : {
		*(.initcallrootfs.init..kmod_initramfs__272_734_populate_rootfs) ;
		*(.initcallrootfs.init..kmod_pci_dma__260_136_pci_iommu_init) ;
	}
}
